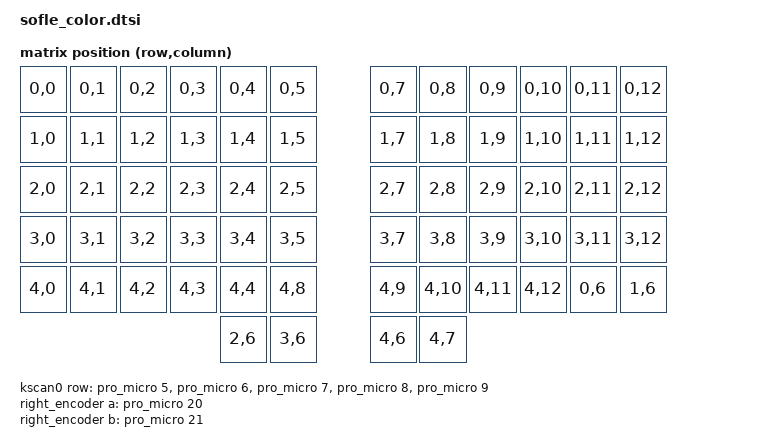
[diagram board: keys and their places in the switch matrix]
#include <dt-bindings/zmk/matrix_transform.h>
#include <zephyr/dt-bindings/gpio/gpio.h>
#include <zephyr/dt-bindings/pinctrl/nrf-pinctrl.h>
/ {
    chosen {
        zmk,kscan = &kscan0;
        zmk,physical-layout = &sc_layout;
    };
    default_transform: keymap_transform_0 {
        compatible = "zmk,matrix-transform";
        columns = <13>;
        rows = <5>;
        map = <
        RC(0,0) RC(0,1) RC(0,2) RC(0,3) RC(0,4) RC(0,5) RC(0,7) RC(0,8) RC(0,9) RC(0,10) RC(0,11) RC(0,12)
        RC(1,0) RC(1,1) RC(1,2) RC(1,3) RC(1,4) RC(1,5) RC(1,7) RC(1,8) RC(1,9) RC(1,10) RC(1,11) RC(1,12)
        RC(2,0) RC(2,1) RC(2,2) RC(2,3) RC(2,4) RC(2,5) RC(2,7) RC(2,8) RC(2,9) RC(2,10) RC(2,11) RC(2,12)
        RC(3,0) RC(3,1) RC(3,2) RC(3,3) RC(3,4) RC(3,5) RC(3,7) RC(3,8) RC(3,9) RC(3,10) RC(3,11) RC(3,12)
        RC(4,0) RC(4,1) RC(4,2) RC(4,3) RC(4,4) RC(4,8) RC(4,9) RC(4,10) RC(4,11) RC(4,12) RC(0,6) RC(1,6)
        RC(2,6) RC(3,6) RC(4,6) RC(4,7)
        >;
    };
    sc_layout: physical_layout_0 {
        compatible = "zmk,physical-layout";
        display-name = "Sofle Color G2";
        transform = <&default_transform>;
        kscan = <&kscan0>;
    };
    kscan0: kscan {
        compatible = "zmk,kscan-gpio-matrix";
        diode-direction = "col2row";
        wakeup-source;
        row-gpios = <&pro_micro 5 (GPIO_ACTIVE_HIGH | GPIO_PULL_DOWN)>,
                    <&pro_micro 6 (GPIO_ACTIVE_HIGH | GPIO_PULL_DOWN)>,
                    <&pro_micro 7 (GPIO_ACTIVE_HIGH | GPIO_PULL_DOWN)>,
                    <&pro_micro 8 (GPIO_ACTIVE_HIGH | GPIO_PULL_DOWN)>,
                    <&pro_micro 9 (GPIO_ACTIVE_HIGH | GPIO_PULL_DOWN)>;
    };
    right_encoder: encoder {
        compatible = "alps,ec11";
        a-gpios = <&pro_micro 20 (GPIO_ACTIVE_HIGH | GPIO_PULL_UP)>;
        b-gpios = <&pro_micro 21 (GPIO_ACTIVE_HIGH | GPIO_PULL_UP)>;
        steps = <80>;
        status = "disabled";
    };
    sensors: sensors {
        compatible = "zmk,keymap-sensors";
        sensors = <&right_encoder>;
        triggers-per-rotation = <20>;
    };
    sc_domains: power_domains {
        compatible = "sofle,power-domains";
        parent-gpios = <&gpio0 13 GPIO_ACTIVE_HIGH>;
        lcd-gate-gpios = <&gpio0 22 (GPIO_ACTIVE_LOW | GPIO_OPEN_DRAIN)>;
        rgb-gate-gpios = <&gpio0 31 (GPIO_ACTIVE_LOW | GPIO_OPEN_DRAIN)>;
        rgb-data-gpios = <&gpio0 20 GPIO_ACTIVE_HIGH>;
    };
};
&uicr { nfct-pins-as-gpios; };
&uart0 { status = "disabled"; };
&i2c0 { status = "disabled"; };
&spi1 { status = "disabled"; };
&{/EXT_POWER} { status = "disabled"; };
&pinctrl {
    sc_spi2_default: sc_spi2_default {
        group1 { psels = <NRF_PSEL(SPIM_SCK, 0, 8)>, <NRF_PSEL(SPIM_MOSI, 0, 6)>; };
    };
    sc_spi2_sleep: sc_spi2_sleep {
        group1 { psels = <NRF_PSEL(SPIM_SCK, 0, 8)>, <NRF_PSEL(SPIM_MOSI, 0, 6)>; low-power-enable; };
    };
};
&spi2 {
    compatible = "nordic,nrf-spim";
    status = "okay";
    pinctrl-0 = <&sc_spi2_default>;
    pinctrl-1 = <&sc_spi2_sleep>;
    pinctrl-names = "default", "sleep";
    cs-gpios = <&gpio0 17 GPIO_ACTIVE_HIGH>;
    dh06_probe: lcd@0 {
        compatible = "sofle,dh06-probe";
        reg = <0>;
        spi-max-frequency = <500000>;
    };
};
